# pwrseq_me12 register map
Registers are access not given, no defined reset value unless marked. A register's access mark holds for its fields unless they carry their own. Offsets are from the block's base; lines under a group give offsets from that group; [hi:lo] are bit positions; {n}, {i} and the like mark numbered series; 'fields as' and 'values as' point back to an identical list; <NAME> marks a mode.

## Memory map
0x40006800 PWRSEQ size 0x400 — Power Sequencer / Low Power Control Register.

## PWRSEQ — Power Sequencer / Low Power Control Register.
Base 0x40006800
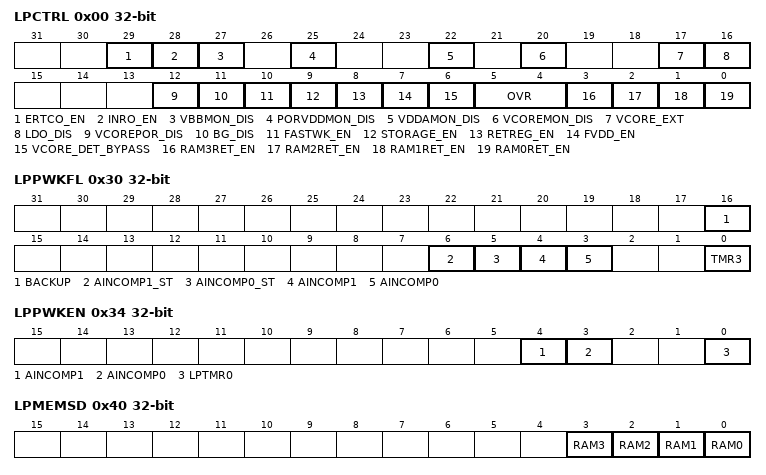
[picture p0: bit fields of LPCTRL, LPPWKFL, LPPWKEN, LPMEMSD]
0x00 LPCTRL — Low Power Control Register.
  [29] ERTCO_EN — Allow LIRC32K to remain on in all Power modes. If STORAGE is set, this bit has no effect.
  [28] INRO_EN — Allow LIRC80K to remain on in all Power modes. If STORAGE is set, this bit has no effect.
  [27] VBBMON_DIS — VDDA Monitor Disable. This bit controls the power monitor on the Analog supply in all operating modes.
  [25] PORVDDMON_DIS — VCORE Power-On Reset Monitor Disable. This bit controls the Power-On Reset monitor on VCORE supply in all operating modes.
  [22] VDDAMON_DIS — VDDA Monitor Disable. This bit controls the power monitor on the Analog supply in all operating modes.
  [20] VCOREMON_DIS — VCORE Monitor Disable. This bit controls the power monitor on the VCORE supply in all operating modes.
  [17] VCORE_EXT — Use external VCORE for 1V supply.
  [16] LDO_DIS — Disable Main LDO. This bit initializes to 1 until the power sequencer determines that no external power source exists on the VCORE pin. At that time, this bit is automatically cleared to 0. If an external power source is detected on the VCORE pin, then this bit will remain at 1.
  [12] VCOREPOR_DIS — VCORE Power-On Reset Monitor Disable. This bit controls the Power-On Reset monitor on VDDC supply in DeepSleep and BACKUP mode.
  [11] BG_DIS — Bandgap OFF. This controls the System Bandgap in DeepSleep mode.
    0=on (Bandgap is always ON.); 1=off (Bandgap is OFF in DeepSleep mode (default).)
  [10] FASTWK_EN — Fast Wake-Up Mode. This bit enables fast wake-up from DeepSleep mode.
  [9] STORAGE_EN — STORAGE mode enable.
  [8] RETREG_EN — Retention Regulator Enable. This bit controls the retention regulator in BACKUP mode. This bit should be 1 all the time if user wants to use retention regulator.
    0=dis (Disable.); 1=en (Enable.)
  [7] FVDD_EN — Flash VDD Enable. FOrce the flash VDD to remain enabled during LP modes.
    0=dis (Flash VDDIO Not Forced.); 1=en (Flash VDDIO Force on.)
  [6] VCORE_DET_BYPASS — Block Auto Detect. Prevent the power sequencer from taking time to detect whether an external power source exists on the VCORE pin. Should always be set to 1 if VCORE is not provided from an external source.
    0=dis (Disable auto detection.); 1=en (Enable auto detection.)
  [5:4] OVR — Operating Voltage Range. The Operating Voltage Range bits (OVR) determine the operating range for VCORE domain.
    0=0_9V; 1=1_0V; 2=1_1V
  [3] RAM3RET_EN — System RAM retention in BACKUP mode. These two bits are used in conjuction with RREGEN bit.
    0=dis (Disable Ram Retention.); 1=en (Enable System RAM 3 retention.)
  [2] RAM2RET_EN — System RAM 2 retention in BACKUP mode. These two bits are used in conjuction with RREGEN bit.
    0=dis (Disable Ram Retention.); 1=en (Enable System RAM 2 retention.)
  [1] RAM1RET_EN — System RAM 1 retention in BACKUP mode. These two bits are used in conjuction with RREGEN bit.
    0=dis (Disable Ram Retention.); 1=en (Enable System RAM 1 retention.)
  [0] RAM0RET_EN — System RAM 0 retention in BACKUP mode. These two bits are used in conjuction with RREGEN bit.
    0=dis (Disable Ram Retention.); 1=en (Enable System RAM 0 retention.)
0x04 LPWKFL0 — Low Power I/O Wakeup Status Flag Register 0. This register indicates the low power wakeup status for GPIO0.
  [30:0] WAKEFL — Wakeup IRQ flags (write ones to clear). One or more of these bits will be set when the corresponding dedicated GPIO pin (s) transition (s) from low to high or high to low. If GPIO wakeup source is selected, using PM.GPIOWKEN register, and the corresponding bit is also selected in LPWKEN register, an interrupt will be gnerated to wake up the CPU from a low power mode.
0x08 LPWKEN0 — Low Power I/O Wakeup Enable Register 0. This register enables low power wakeup functionality for GPIO0.
  [30:0] WAKEEN — Enable wakeup. These bits allow wakeup from the corresponding GPIO pin (s) on transition (s) from low to high or high to low when PM.GPIOWKEN is set. Wakeup status is indicated in PPWKST register.
0x30 LPPWKFL — Low Power Peripheral Wakeup Status Flag Register.
  [16] BACKUP — Backup Mode Wakeup Flag.
  [6] AINCOMP1_ST — Analog Input Comparator 1 Status.
  [5] AINCOMP0_ST — Analog Input Comparator 0 Status.
  [4] AINCOMP1 — Analog Input Comparator 1 Wakeup Flag.
  [3] AINCOMP0 — Analog Input Comparator 0 Wakeup Flag.
  [0] TMR3 — TMR3 (LPTMR0) Wakeup Flag.
0x34 LPPWKEN — Low Power Peripheral Wakeup Enable Register.
  [4] AINCOMP1 — AINCOMP1 Wakeup Enable. This bit allows wakeup from the AINCOMP1.
  [3] AINCOMP0 — AINCOMP0 Wakeup Enable. This bit allows wakeup from the AINCOMP0.
  [0] LPTMR0 — LPTMR0 Wakeup Enable. This bit allows wakeup from the LPTIMER0.
0x40 LPMEMSD — Low Power Memory Shutdown Register.
  [3] RAM3 — System RAM block 2 Shut Down.
  [2] RAM2 — System RAM block 2 Shut Down.
  [1] RAM1 — Systen RAM block 1 Shut Down.
  [0] RAM0 — System RAM block 0 Shut Down.
